AUTOSAR XML (schema 4-2-1)
standard types defined: float32, float64, sint8, sint16, sint32, uint8, uint16, uint32, boolean, dtRef_VOID, Float32, Boolean, UInt32
package /FoundationPkg/FoundationArchitecturePkg
  constant specification iAssistTorque_AssistanceTorque_Init: value-spec={short-label=iAssistTorque_AssistanceTorque_Init, fields=[0 Nm, 0]}
  sender receiver interface iAssistTorque
    data AssistanceTorque: sw-calibration-access=READ-ONLY, type=tAssistTorque, init-value=constant-reference=iAssistTorque_AssistanceTorque_Init
  constant specification iAssistCapability_Capability_Init: value-spec={short-label=iAssistCapability_Capability_Init, fields=[0 %, 0 %]}
  sender receiver interface iAssistCapability
    data Capability: sw-calibration-access=READ-ONLY, type=tAssistCapability, init-value=constant-reference=iAssistCapability_Capability_Init
  constant specification iAssistCapabilityLimit_CapabilityLimit_Init: value-spec=0 %
  sender receiver interface iAssistCapabilityLimit
    data CapabilityLimit: sw-calibration-access=READ-ONLY, type=Percent, init-value=constant-reference=iAssistCapabilityLimit_CapabilityLimit_Init
  constant specification iVehicleData_VehicleSpeed_Init: value-spec={short-label=iVehicleData_VehicleSpeed_Init, fields=[0 Kph, 0, 0]}
  constant specification iVehicleData_EstimatedSteeringPosition_Init: value-spec={short-label=iVehicleData_EstimatedSteeringPosition_Init, fields=[0 deg, 0, 0 %]}
  constant specification iVehicleData_YawRate_Init: value-spec={short-label=iVehicleData_YawRate_Init, fields=[0 deg/S, 0]}
  sender receiver interface iVehicleData
    data VehicleSpeed: sw-calibration-access=READ-ONLY, type=tVehicleSpd, init-value=constant-reference=iVehicleData_VehicleSpeed_Init
    data EstimatedSteeringPosition: sw-calibration-access=READ-ONLY, type=tEstimatedSteeringPosition, init-value=constant-reference=iVehicleData_EstimatedSteeringPosition_Init
    data YawRate: sw-calibration-access=READ-ONLY, type=tYawRateData, init-value=constant-reference=iVehicleData_YawRate_Init
  5 x constant specification:
    iColumnData_ColumnTorque_Init: value-spec={short-label=iColumnData_ColumnTorque_Init, fields=[0 Nm, 0 Nm/s, 0]}
    iColumnData_SteeringPositionLower_Init: value-spec={short-label=iColumnData_SteeringPositionLower_Init, fields=[0 deg, 0, {short-label=tColumnPosition_EQf_Init, fields=[1, 1, 1, 1]}]}
    iColumnData_ColumnVelocity_Init: value-spec={short-label=iColumnData_ColumnVelocity_Init, fields=[0 revs/S, 0 revs/S, 0]}
    iColumnData_SteeringPositionUpper_Init: value-spec={short-label=iColumnData_SteeringPositionUpper_Init, fields=[0 deg, 0, {short-label=tColumnPosition_EQf_Init, fields=[1, 1, 1, 1]}]}
    iColumnData_ColumnPositionLower_Init: value-spec={short-label=iColumnData_ColumnPositionLower_Init, fields=[0 deg, 0, {short-label=tColumnPosition_EQf_Init, fields=[1, 1, 1, 1]}]}
  sender receiver interface iColumnData
    5 x data, all with sw-calibration-access=READ-ONLY:
      ColumnTorque: type=tInputTorque, init-value=constant-reference=iColumnData_ColumnTorque_Init
      SteeringPositionLower: type=tColumnPosition, init-value=constant-reference=iColumnData_SteeringPositionLower_Init
      ColumnVelocity: type=tColumnVelocity, init-value=constant-reference=iColumnData_ColumnVelocity_Init
      SteeringPositionUpper: type=tColumnPosition, init-value=constant-reference=iColumnData_SteeringPositionUpper_Init
      ColumnPositionLower: type=tColumnPosition, init-value=constant-reference=iColumnData_ColumnPositionLower_Init
  client server interface iRack
    8 x operation:
      getMaxPhysicalAssist
        arg maxPhysicalAssist: type=Nm, direction=OUT
      initialisationColumnAngle
        arg pinionAngle: type=Degrees, direction=IN
      translateColumnAngleToRackPosition
        arg pinionAngle: type=Degrees, direction=IN
        arg rackPosition: type=mm, direction=OUT
      translateColumnTorqueToRackForce
        arg columnTorque: type=Nm, direction=IN
        arg rackForce: type=kN, direction=OUT
      translateRackPositionToColumnAngle
        arg rackPosition: type=mm, direction=IN
        arg columnAngle: type=Degrees, direction=OUT
      translateRackForceToColumnTorque
        arg rackForce: type=kN, direction=IN
        arg columnTorque: type=Nm, direction=OUT
      translateColumnVelocityToRackVelocity
        arg columnVelocity: type=DegreesPerSec, direction=IN
        arg rackVelocity: type=mmPerSec, direction=OUT
      translateRackVelocityToColumnVelocity
        arg rackVelocity: type=mmPerSec, direction=IN
        arg columnVelocity: type=DegreesPerSec, direction=OUT
  constant specification iFitness_ControllerFitness_Init: value-spec=3
  sender receiver interface iFitness
    data ControllerFitness: sw-calibration-access=READ-ONLY, type=tQualityFactor, init-value=constant-reference=iFitness_ControllerFitness_Init
  client server interface iElectricDriveControl
    operation enable
    operation getEnableState
      4 x arg, all with direction=OUT:
        state: type=tEnableState
        bridge1Health: type=tHealthStatus
        bridge2Health: type=tHealthStatus
        maxTimeCapability: type=tMaxTimeCapability
    operation disable
  constant specification iAssistStates_AssistState_Init: value-spec={short-label=iAssistStates_AssistState_Init, fields=[0, 1]}
  sender receiver interface iAssistStates
    data AssistState: sw-calibration-access=READ-ONLY, type=tAssistStates, init-value=constant-reference=iAssistStates_AssistState_Init
  constant specification iSegControl_SegEnStatus_Init: value-spec=0
  constant specification iSegControl_SegMode_Init: value-spec=0
  constant specification iSegControl_SegElecDrvDisableReq_Init: value-spec=0
  sender receiver interface iSegControl
    data SegEnStatus: sw-calibration-access=READ-ONLY, type=Boolean, init-value=constant-reference=iSegControl_SegEnStatus_Init
    data SegMode: sw-calibration-access=READ-ONLY, type=tSegMode, init-value=constant-reference=iSegControl_SegMode_Init
    data SegElecDrvDisableReq: sw-calibration-access=READ-ONLY, type=Boolean, init-value=constant-reference=iSegControl_SegElecDrvDisableReq_Init
  client server interface iOveruseControl
    operation setOveruseInhibition
      arg RequestInhibition: type=Boolean, direction=IN
package /FoundationPkg/FoundationArchitecturePkg/FoundationControllerPkg
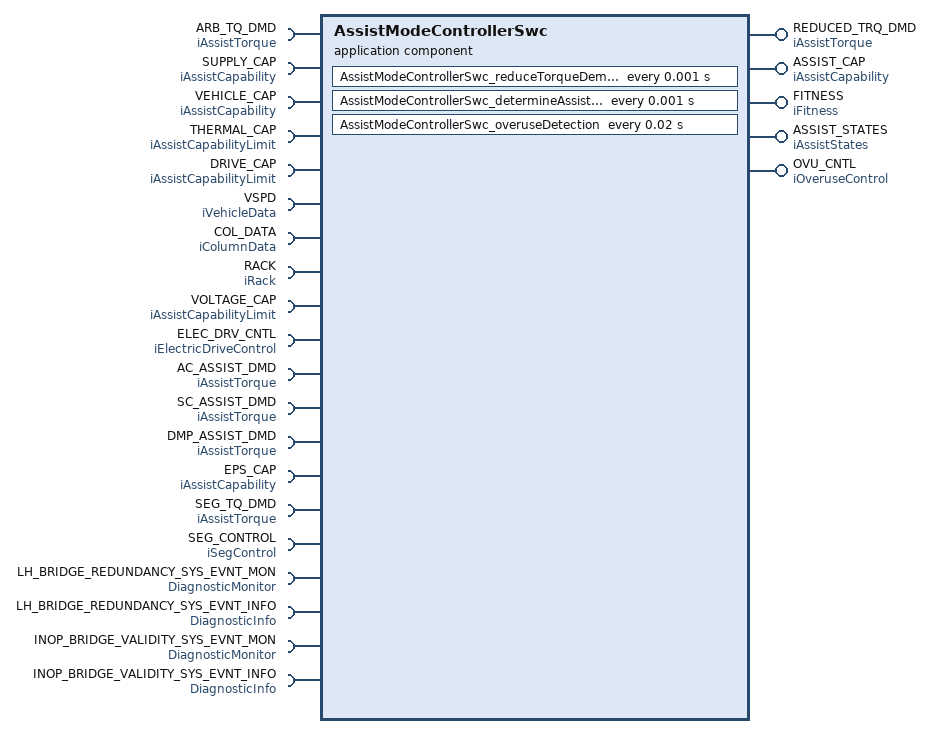
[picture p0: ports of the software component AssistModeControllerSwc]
  application sw component type AssistModeControllerSwc  # Based on the input states representing the capability of either the vehicle or the components of the EPS System reduce the assistance torque demand to prevent that demand exceeding the current capability of the input with the lowest capability. The function must also take account of any reinstatement of system capability from exceeding the maximum rate of torque reinstatement.
    require port ARB_TQ_DMD: nonqueued-receiver-com-spec{data-element=AssistanceTorque, init-value=constant-reference=iAssistTorque_AssistanceTorque_Init}, required-interface=iAssistTorque
    provide port REDUCED_TRQ_DMD: nonqueued-sender-com-spec{data-element=AssistanceTorque, init-value=constant-reference=iAssistTorque_AssistanceTorque_Init}, provided-interface=iAssistTorque
    6 x require port:
      SUPPLY_CAP: nonqueued-receiver-com-spec{data-element=Capability, init-value=constant-reference=iAssistCapability_Capability_Init}, required-interface=iAssistCapability
      VEHICLE_CAP: nonqueued-receiver-com-spec{data-element=Capability, init-value=constant-reference=iAssistCapability_Capability_Init}, required-interface=iAssistCapability
      THERMAL_CAP: nonqueued-receiver-com-spec{data-element=CapabilityLimit, init-value=constant-reference=iAssistCapabilityLimit_CapabilityLimit_Init}, required-interface=iAssistCapabilityLimit
      DRIVE_CAP: nonqueued-receiver-com-spec{data-element=CapabilityLimit, init-value=constant-reference=iAssistCapabilityLimit_CapabilityLimit_Init}, required-interface=iAssistCapabilityLimit
      VSPD: required-interface=iVehicleData
        required-com-specs:
          data-element=VehicleSpeed, init-value=constant-reference=iVehicleData_VehicleSpeed_Init
          data-element=EstimatedSteeringPosition, init-value=constant-reference=iVehicleData_EstimatedSteeringPosition_Init
          data-element=YawRate, init-value=constant-reference=iVehicleData_YawRate_Init
      COL_DATA: required-interface=iColumnData
        required-com-specs:
          data-element=ColumnTorque, init-value=constant-reference=iColumnData_ColumnTorque_Init
          data-element=SteeringPositionLower, init-value=constant-reference=iColumnData_SteeringPositionLower_Init
          data-element=ColumnVelocity, init-value=constant-reference=iColumnData_ColumnVelocity_Init
          data-element=SteeringPositionUpper, init-value=constant-reference=iColumnData_SteeringPositionUpper_Init
          data-element=ColumnPositionLower, init-value=constant-reference=iColumnData_ColumnPositionLower_Init
    provide port ASSIST_CAP: nonqueued-sender-com-spec{data-element=Capability, init-value=constant-reference=iAssistCapability_Capability_Init}, provided-interface=iAssistCapability
    require port RACK: required-interface=iRack
    provide port FITNESS: nonqueued-sender-com-spec{data-element=ControllerFitness, init-value=constant-reference=iFitness_ControllerFitness_Init}, provided-interface=iFitness
    require port VOLTAGE_CAP: nonqueued-receiver-com-spec{data-element=CapabilityLimit, init-value=constant-reference=iAssistCapabilityLimit_CapabilityLimit_Init}, required-interface=iAssistCapabilityLimit
    require port ELEC_DRV_CNTL: required-interface=iElectricDriveControl
    provide port ASSIST_STATES: nonqueued-sender-com-spec{data-element=AssistState, init-value=constant-reference=iAssistStates_AssistState_Init}, provided-interface=iAssistStates
    6 x require port:
      AC_ASSIST_DMD: nonqueued-receiver-com-spec{data-element=AssistanceTorque, init-value=constant-reference=iAssistTorque_AssistanceTorque_Init}, required-interface=iAssistTorque
      SC_ASSIST_DMD: nonqueued-receiver-com-spec{data-element=AssistanceTorque, init-value=constant-reference=iAssistTorque_AssistanceTorque_Init}, required-interface=iAssistTorque
      DMP_ASSIST_DMD: nonqueued-receiver-com-spec{data-element=AssistanceTorque, init-value=constant-reference=iAssistTorque_AssistanceTorque_Init}, required-interface=iAssistTorque
      EPS_CAP: nonqueued-receiver-com-spec{data-element=Capability, init-value=constant-reference=iAssistCapability_Capability_Init}, required-interface=iAssistCapability  # The EPS assist capability, as a result of EPS diagnostic monitoring
      SEG_TQ_DMD: nonqueued-receiver-com-spec{data-element=AssistanceTorque, init-value=constant-reference=iAssistTorque_AssistanceTorque_Init}, required-interface=iAssistTorque
      SEG_CONTROL: required-interface=iSegControl
        required-com-specs:
          data-element=SegEnStatus, init-value=constant-reference=iSegControl_SegEnStatus_Init
          data-element=SegMode, init-value=constant-reference=iSegControl_SegMode_Init
          data-element=SegElecDrvDisableReq, init-value=constant-reference=iSegControl_SegElecDrvDisableReq_Init
    provide port OVU_CNTL: server-com-spec{operation=setOveruseInhibition, queue-length=1}, provided-interface=iOveruseControl
    4 x require port:
      LH_BRIDGE_REDUNDANCY_SYS_EVNT_MON: required-interface=DiagnosticMonitor
      LH_BRIDGE_REDUNDANCY_SYS_EVNT_INFO: required-interface=DiagnosticInfo
      INOP_BRIDGE_VALIDITY_SYS_EVNT_MON: required-interface=DiagnosticMonitor
      INOP_BRIDGE_VALIDITY_SYS_EVNT_INFO: required-interface=DiagnosticInfo
    behavior AssistModeControllerSwc_IB: data-type-mapping=MappingSet, handle-termination-and-restart=NO-SUPPORT
      timing event Event_reduceTorqueDemand: start-on-event=AssistModeControllerSwc_reduceTorqueDemand, period=0.001
      timing event Event_determineAssistState: start-on-event=AssistModeControllerSwc_determineAssistState, period=0.001
      timing event Event_overuseDetection: start-on-event=AssistModeControllerSwc_overuseDetection, period=0.02
      init event Event_initialiser_Init: start-on-event=AssistModeControllerSwc_initialiser
      operation invoked event Event_setOveruseInhibition: start-on-event=AssistModeControllerSwc_setOveruseInhibition, operation=OVU_CNTL.setOveruseInhibition
      explicit-inter-runnable-variables:
        data OveruseInhibited: sw-calibration-access=READ-ONLY, type=Boolean, init-value=constant-reference=AssistModeControllerSwc_OveruseInhibited_Init  # The IRV indicates if there is one source requesting overuse suppressing.
      implicit-inter-runnable-variables:
        6 x data, all with sw-calibration-access=READ-ONLY:
          OveruseCapability_Limit: type=Percent, init-value=constant-reference=OveruseCapability_Limit_Init  # Limit as a percentage of the total system assist capability.
          OveruseCapability_Scale: type=Percent, init-value=constant-reference=OveruseCapability_Scale_Init  # Limit as a percentage of the assistance demand i.e. reducing the demand by a percentage.
          AssistStateCapability_Limit: type=Percent, init-value=constant-reference=AssistStateCapability_Limit_Init  # Limit as a percentage of the total system assist capability.
          AssistStateCapability_Scale: type=Percent, init-value=constant-reference=AssistStateCapability_Scale_Init  # Limit as a percentage of the assistance demand i.e. reducing the demand by a percentage.
          RedAssistanceTorque_Value: type=Nm, init-value=constant-reference=RedAssistanceTorque_Value_Init
          RedAssistanceTorque_Qf: type=tQualityFactor, init-value=constant-reference=RedAssistanceTorque_Qf_Init
      per-instance-parameters:
        13 x parameter data prototype, all with category=VALUE, sw-addr-method=PlatformTune, sw-calibration-access=READ-WRITE:
          OVERUSE_LIMIT_VSPD_THRESHOLD: type=Kph_0_0_to_400_0, init-value=constant-reference=PlatformTune_OVERUSE_LIMIT_VSPD_THRESHOLD_Init  # Vehicle speed above which overuse will not reduce assist.
          OVERUSE_COLUMN_VELOCITY_THRESHOLD: type=RevsPerSec_0_0_to_0_5, init-value=constant-reference=PlatformTune_OVERUSE_COLUMN_VELOCITY_THRESHOLD_Init  # Column Velocity threshold above which Overuse will not reduce assist.
          OVERUSE_INITIATION_TIME: type=ms_0_to_2500, init-value=constant-reference=PlatformTune_OVERUSE_INITIATION_TIME_Init  # Time overuse conditions must be present before overuse starts to reduce assist.
          OVERUSE_TORQUE_LIMIT_VALUE: type=Percent_0_0_to_1_0, init-value=constant-reference=PlatformTune_OVERUSE_TORQUE_LIMIT_VALUE_Init  # Column torque value below which overuse will not reduce assist.
          OVERUSE_TORQUE_LIMIT_DOWN_SLEW_RATE: type=PercentPerSec_0_1_to_50_0, init-value=constant-reference=PlatformTune_OVERUSE_TORQUE_LIMIT_DOWN_SLEW_RATE_Init  # Slew rate for overuse to ramp assist down.
          OVERUSE_TORQUE_LIMIT_UP_SLEW_RATE: type=PercentPerSec_0_1_to_50_0, init-value=constant-reference=PlatformTune_OVERUSE_TORQUE_LIMIT_UP_SLEW_RATE_Init  # Slew rate for overuse to ramp assist back in.
          OVERUSE_UPPER_ASSIST_TORQUE_PERCENT_THRESHOLD: type=Percent_0_to_1, init-value=constant-reference=PlatformTune_OVERUSE_UPPER_ASSIST_TORQUE_PERCENT_THRESHOLD_Init  # Target assist level for overuse to reduce torque to.
          OVERUSE_LOWER_ASSIST_TORQUE_PERCENT_THRESHOLD: type=Percent_0_to_1, init-value=constant-reference=PlatformTune_OVERUSE_LOWER_ASSIST_TORQUE_PERCENT_THRESHOLD_Init  # Target assist level for overuse to reduce torque to.
          SUDDEN_CHANGE_INC_TRQ_SFB: type=PercentPerSec_1_to_100, init-value=constant-reference=PlatformTune_SUDDEN_CHANGE_INC_TRQ_SFB_Init  # This parameter represents the maximum rate at which assist can be ramped up. It is used to rampup the voltage, thermal and drive capabilities from the EPP.
          LIMP_HOME_EPP_CAPABILITY_TRANSITION_TIME: type=ms_500_to_5000, init-value=constant-reference=PlatformTune_LIMP_HOME_EPP_CAPABILITY_TRANSITION_TIME_Init  # Time to transition to the reduced (scale) assist after an EPP failure resulting in reduced EPP capability. A smooth transition ramp will be used from the current assist capability to the reduce capability.
          LIMP_HOME_TARGET_CAP_LIMIT: type=Percent_0_to_1, init-value=constant-reference=PlatformTune_LIMP_HOME_TARGET_CAP_LIMIT_Init  # Maximal provided assist in percentage (calculated based on max physical assist) whilst limp home mode.
          LIMP_HOME_TARGET_CAP_SCALE: type=Percent_0_to_1, init-value=constant-reference=PlatformTune_LIMP_HOME_TARGET_CAP_SCALE_Init  # Boost curve scale factor in percentage whilst limp home mode.
          LIMITED_ASSIST_WITH_OVERUSE: type=Boolean, init-value=constant-reference=PlatformTune_LIMITED_ASSIST_WITH_OVERUSE_Init  # Tune controls if the an overuse case shall cause a limited assit. The torque reduction due to overuse will always happen independently from this tune. True: an overuse case will cause a limited asssit False: an overuse case will not cause a limited assist
      5 x runnable:
        AssistModeControllerSwc_reduceTorqueDemand: symbol=AssistModeController_reduceTorqueDemand  # Reduce the torque demand by applying the lowest of the input torque demands. Two types of limiting are supported: SCALE - reduce the torque by a percentage of the assistance torque demand. LIMIT - limit the torque by a percentage of the maximum assist capability of the EPS system. This function shall also guard against large step changes in torque reinstatement by enforcing a maximum reinstatement torque limit (SUDDEN_CHANGE_INC_TRQ_SFB).
          data-read-access:
            access R_ARB_TQ_DMD_AssistanceTorque: accessed-variable=ARB_TQ_DMD.AssistanceTorque
            access R_VSPD_VehicleSpeed: accessed-variable=VSPD.VehicleSpeed
            access R_SEG_TQ_DMD_AssistanceTorque: accessed-variable=SEG_TQ_DMD.AssistanceTorque
          data-write-access:
            access W_REDUCED_TRQ_DMD_AssistanceTorque: accessed-variable=REDUCED_TRQ_DMD.AssistanceTorque
          parameter access SUDDEN_CHANGE_INC_TRQ_SFB: accessed-parameter=SUDDEN_CHANGE_INC_TRQ_SFB
          read-local-variables:
            access RV_AssistStateCapability_Limit: accessed-variable=AssistStateCapability_Limit
            access RV_AssistStateCapability_Scale: accessed-variable=AssistStateCapability_Scale
          sync call Call_RACK_getMaxPhysicalAssist: operation=RACK.getMaxPhysicalAssist
          written-local-variables:
            access WV_RedAssistanceTorque_Value: accessed-variable=RedAssistanceTorque_Value
            access WV_RedAssistanceTorque_Qf: accessed-variable=RedAssistanceTorque_Qf
        AssistModeControllerSwc_determineAssistState: symbol=AssistModeController_determineAssistState  # This runnable determines the assist states based on the assist capability and environment condition of the system. Assist states are used to determine the system states (Fully assisted, Limited assisted or failure conditions). Assist states directly controls the assist level or the system and this is one of the important feature which decides the reduction in the torque demand to motor. Assist states are also necessary to the fault tolerance of the system and take preventive measures.
          data-read-access:
            14 x access:
              R_COL_DATA_ColumnTorque: accessed-variable=COL_DATA.ColumnTorque
              R_COL_DATA_ColumnVelocity: accessed-variable=COL_DATA.ColumnVelocity
              R_SUPPLY_CAP_Capability: accessed-variable=SUPPLY_CAP.Capability
              R_VEHICLE_CAP_Capability: accessed-variable=VEHICLE_CAP.Capability
              R_THERMAL_CAP_CapabilityLimit: accessed-variable=THERMAL_CAP.CapabilityLimit
              R_DRIVE_CAP_CapabilityLimit: accessed-variable=DRIVE_CAP.CapabilityLimit
              R_VOLTAGE_CAP_CapabilityLimit: accessed-variable=VOLTAGE_CAP.CapabilityLimit
              R_AC_ASSIST_DMD_AssistanceTorque: accessed-variable=AC_ASSIST_DMD.AssistanceTorque
              R_SC_ASSIST_DMD_AssistanceTorque: accessed-variable=SC_ASSIST_DMD.AssistanceTorque
              R_DMP_ASSIST_DMD_AssistanceTorque: accessed-variable=DMP_ASSIST_DMD.AssistanceTorque
              R_EPS_CAP_Capability: accessed-variable=EPS_CAP.Capability
              R_SEG_CONTROL_SegEnStatus: accessed-variable=SEG_CONTROL.SegEnStatus
              R_SEG_CONTROL_SegMode: accessed-variable=SEG_CONTROL.SegMode
              R_SEG_CONTROL_SegElecDrvDisableReq: accessed-variable=SEG_CONTROL.SegElecDrvDisableReq
          data-write-access:
            access W_FITNESS_ControllerFitness: accessed-variable=FITNESS.ControllerFitness
            access W_ASSIST_CAP_Capability: accessed-variable=ASSIST_CAP.Capability
            access W_ASSIST_STATES_AssistState: accessed-variable=ASSIST_STATES.AssistState
          4 x parameter access:
            LIMP_HOME_EPP_CAPABILITY_TRANSITION_TIME: accessed-parameter=LIMP_HOME_EPP_CAPABILITY_TRANSITION_TIME
            LIMP_HOME_TARGET_CAP_LIMIT: accessed-parameter=LIMP_HOME_TARGET_CAP_LIMIT
            LIMP_HOME_TARGET_CAP_SCALE: accessed-parameter=LIMP_HOME_TARGET_CAP_SCALE
            LIMITED_ASSIST_WITH_OVERUSE: accessed-parameter=LIMITED_ASSIST_WITH_OVERUSE
          read-local-variables:
            access RV_OveruseCapability_Limit: accessed-variable=OveruseCapability_Limit
            access RV_OveruseCapability_Scale: accessed-variable=OveruseCapability_Scale
          10 x sync call:
            Call_ELEC_DRV_CNTL_getEnableState: operation=ELEC_DRV_CNTL.getEnableState
            Call_ELEC_DRV_CNTL_disable: operation=ELEC_DRV_CNTL.disable
            Call_INOP_BRIDGE_VALIDITY_SYS_EVNT_SetEventStatus: operation=INOP_BRIDGE_VALIDITY_SYS_EVNT_MON.SetEventStatus
            Call_INOP_BRIDGE_VALIDITY_SYS_EVNT_ResetEventStatus: operation=INOP_BRIDGE_VALIDITY_SYS_EVNT_MON.ResetEventDebounceStatus
            Call_INOP_BRIDGE_VALIDITY_SYS_EVNT_GetEventStatus: operation=INOP_BRIDGE_VALIDITY_SYS_EVNT_INFO.GetEventStatus
            Call_INOP_BRIDGE_VALIDITY_SYS_EVNT_GetEventFailed: operation=INOP_BRIDGE_VALIDITY_SYS_EVNT_INFO.GetEventFailed
            Call_LH_BRIDGE_REDUNDANCY_SYS_EVNT_SetEventStatus: operation=LH_BRIDGE_REDUNDANCY_SYS_EVNT_MON.SetEventStatus
            Call_LH_BRIDGE_REDUNDANCY_SYS_EVNT_ResetEventStatus: operation=LH_BRIDGE_REDUNDANCY_SYS_EVNT_MON.ResetEventDebounceStatus
            Call_LH_BRIDGE_REDUNDANCY_SYS_EVNT_GetEventStatus: operation=LH_BRIDGE_REDUNDANCY_SYS_EVNT_INFO.GetEventStatus
            Call_LH_BRIDGE_REDUNDANCY_SYS_EVNT_GetEventFailed: operation=LH_BRIDGE_REDUNDANCY_SYS_EVNT_INFO.GetEventFailed
          written-local-variables:
            access WV_AssistStateCapability_Limit: accessed-variable=AssistStateCapability_Limit
            access WV_AssistStateCapability_Scale: accessed-variable=AssistStateCapability_Scale
        AssistModeControllerSwc_overuseDetection: symbol=AssistModeController_overuseDetection  # The purpose of the overuse function is to take early intervention to reduce the torque demand in conditions when the EPP may start to get hot (high torque demand, low column velocities). Overuse takes action to reduce the torque demand thereby preventing the system going into thermal derating. By taking preventative action the system will not have got warm and derated when the steering is required again. Detect the conditions for system overuse and when present request a reduction in the torque demand.
          data-read-access:
            4 x access:
              R_VSPD_VehicleSpeed: accessed-variable=VSPD.VehicleSpeed
              R_COL_DATA_ColumnVelocity: accessed-variable=COL_DATA.ColumnVelocity
              R_ARB_TQ_DMD_AssistanceTorque: accessed-variable=ARB_TQ_DMD.AssistanceTorque
              R_SEG_TQ_DMD_AssistanceTorque: accessed-variable=SEG_TQ_DMD.AssistanceTorque
          8 x parameter access:
            OVERUSE_COLUMN_VELOCITY_THRESHOLD: accessed-parameter=OVERUSE_COLUMN_VELOCITY_THRESHOLD
            OVERUSE_INITIATION_TIME: accessed-parameter=OVERUSE_INITIATION_TIME
            OVERUSE_LIMIT_VSPD_THRESHOLD: accessed-parameter=OVERUSE_LIMIT_VSPD_THRESHOLD
            OVERUSE_TORQUE_LIMIT_DOWN_SLEW_RATE: accessed-parameter=OVERUSE_TORQUE_LIMIT_DOWN_SLEW_RATE
            OVERUSE_TORQUE_LIMIT_UP_SLEW_RATE: accessed-parameter=OVERUSE_TORQUE_LIMIT_UP_SLEW_RATE
            OVERUSE_TORQUE_LIMIT_VALUE: accessed-parameter=OVERUSE_TORQUE_LIMIT_VALUE
            OVERUSE_LOWER_ASSIST_TORQUE_PERCENT_THRESHOLD: accessed-parameter=OVERUSE_LOWER_ASSIST_TORQUE_PERCENT_THRESHOLD
            OVERUSE_UPPER_ASSIST_TORQUE_PERCENT_THRESHOLD: accessed-parameter=OVERUSE_UPPER_ASSIST_TORQUE_PERCENT_THRESHOLD
          read-local-variables:
            access RV_RedAssistanceTorque_Value: accessed-variable=RedAssistanceTorque_Value
            access RV_RedAssistanceTorque_Qf: accessed-variable=RedAssistanceTorque_Qf
            access RV_OveruseInhibited: accessed-variable=OveruseInhibited
          sync call Call_RACK_getMaxPhysicalAssist: operation=RACK.getMaxPhysicalAssist
          written-local-variables:
            access WV_OveruseCapability_Limit: accessed-variable=OveruseCapability_Limit
            access WV_OveruseCapability_Scale: accessed-variable=OveruseCapability_Scale
        AssistModeControllerSwc_initialiser: symbol=AssistModeController_initialiser
        AssistModeControllerSwc_setOveruseInhibition: symbol=AssistModeController_setOveruseInhibition  # Interface requests the inhibition of an possible overuse torque reduction. 1. RequestInhibition set to true: torque shall not be reduced due to overuse. 2. RequestInhibition set to false: torque shall be reduced due to overuse. The interface is reenterable. Each client is required to clear the inhibition by setting RequestInhibition to false once the inhibition is no longer needed. Otherwise the overuse will stay inhibited till end of the current ignition.
          written-local-variables:
            access WV_OveruseInhibited: accessed-variable=OveruseInhibited
      4 x swc service dependency:
        Monitor_LH_BRIDGE_REDUNDANCY_SYS_EVNT: assigned-ports=role-based-port-assignment={port-prototype=LH_BRIDGE_REDUNDANCY_SYS_EVNT_MON, role=DiagnosticMonitor}
          service-needs:
            diagnostic event needs EventNeed_LH_BRIDGE_REDUNDANCY_SYS_EVNT
        Info_LH_BRIDGE_REDUNDANCY_SYS_EVNT: assigned-ports=role-based-port-assignment={port-prototype=LH_BRIDGE_REDUNDANCY_SYS_EVNT_INFO, role=DiagnosticInfo}
          service-needs:
            diagnostic event info needs InfoNeed_LH_BRIDGE_REDUNDANCY_SYS_EVNT
        Monitor_INOP_BRIDGE_VALIDITY_SYS_EVNT: assigned-ports=role-based-port-assignment={port-prototype=INOP_BRIDGE_VALIDITY_SYS_EVNT_MON, role=DiagnosticMonitor}
          service-needs:
            diagnostic event needs EventNeed_INOP_BRIDGE_VALIDITY_SYS_EVNT
        Info_INOP_BRIDGE_VALIDITY_SYS_EVNT: assigned-ports=role-based-port-assignment={port-prototype=INOP_BRIDGE_VALIDITY_SYS_EVNT_INFO, role=DiagnosticInfo}
          service-needs:
            diagnostic event info needs InfoNeed_INOP_BRIDGE_VALIDITY_SYS_EVNT
  14 x constant specification:
    AssistModeControllerSwc_OveruseInhibited_Init: value-spec=0
    PlatformTune_OVERUSE_LIMIT_VSPD_THRESHOLD_Init: value-spec=2.0
    PlatformTune_OVERUSE_COLUMN_VELOCITY_THRESHOLD_Init: value-spec=0.1
    PlatformTune_OVERUSE_INITIATION_TIME_Init: value-spec=500
    PlatformTune_OVERUSE_TORQUE_LIMIT_VALUE_Init: value-spec=0.6
    PlatformTune_OVERUSE_TORQUE_LIMIT_DOWN_SLEW_RATE_Init: value-spec=0.63
    PlatformTune_OVERUSE_TORQUE_LIMIT_UP_SLEW_RATE_Init: value-spec=1.0
    PlatformTune_OVERUSE_UPPER_ASSIST_TORQUE_PERCENT_THRESHOLD_Init: value-spec=0.95
    PlatformTune_OVERUSE_LOWER_ASSIST_TORQUE_PERCENT_THRESHOLD_Init: value-spec=0.6
    PlatformTune_SUDDEN_CHANGE_INC_TRQ_SFB_Init: value-spec=1.0
    PlatformTune_LIMP_HOME_EPP_CAPABILITY_TRANSITION_TIME_Init: value-spec=1000
    PlatformTune_LIMP_HOME_TARGET_CAP_LIMIT_Init: value-spec=0.5
    PlatformTune_LIMP_HOME_TARGET_CAP_SCALE_Init: value-spec=0.5
    PlatformTune_LIMITED_ASSIST_WITH_OVERUSE_Init: value-spec=1
package /FoundationPkg/FoundationArchitecturePkg/FoundationTypes
  unit Nm_Unit: display-name=Nm
  impl type Nm: implementation-data-type=Float32
  compu method tQualityFactor_Compu: 0=QF_UNINITIALIZED, 0=QF_UNINITIALISED, 1=QF_UNAVAILABLE, 2=QF_DEGRADED, 3=QF_FULL
  impl type tQualityFactor: category=VALUE, base-type=sint32, compu-method=tQualityFactor_Compu
  impl type tAssistTorque: category=STRUCTURE
    element Value: implementation-data-type=Nm
    element Qf: implementation-data-type=tQualityFactor
  unit Percent_Unit: display-name=%
  impl type Percent: implementation-data-type=Float32
  impl type tAssistCapability: category=STRUCTURE
    element Limit: implementation-data-type=Percent
    element Scale: implementation-data-type=Percent
  unit Kph_Unit: display-name=Kph
  impl type Kph: implementation-data-type=Float32
  impl type tVehicleSpd: category=STRUCTURE
    element Filtered: implementation-data-type=Kph
    element Moving: implementation-data-type=Boolean
    element Qf: implementation-data-type=tQualityFactor
  unit Degrees_Unit: display-name=deg
  impl type Degrees: implementation-data-type=Float32
  impl type tEstimatedSteeringPosition: category=STRUCTURE
    element Value: implementation-data-type=Degrees
    element Qf: implementation-data-type=tQualityFactor
    element Confidence: implementation-data-type=Percent
  unit DegreesPerSec_Unit: display-name=deg/S
  impl type DegreesPerSec: implementation-data-type=Float32
  impl type tYawRateData: category=STRUCTURE
    element Value: implementation-data-type=DegreesPerSec
    element Qf: implementation-data-type=tQualityFactor
  unit NmPerSec_Unit: display-name=Nm/s
  4 x impl type:
    NmPerSec: implementation-data-type=Float32
    tInputTorque: category=STRUCTURE
      element Value: implementation-data-type=Nm
      element Derivative: implementation-data-type=NmPerSec
      element Qf: implementation-data-type=tQualityFactor
    tExtendedQf: category=STRUCTURE
      4 x element, all with category=TYPE_REFERENCE, implementation-data-type=Boolean:
        IntegrityDegraded
        ResolutionDegraded
        LossOfRedundancy
        Defaulted
    tColumnPosition: category=STRUCTURE
      element Value: implementation-data-type=Degrees
      element Qf: implementation-data-type=tQualityFactor
      element EQf: implementation-data-type=tExtendedQf
  unit RevsPerSec_Unit: display-name=revs/S
  impl type RevsPerSec: implementation-data-type=Float32
  impl type tColumnVelocity: category=STRUCTURE
    element Filtered: implementation-data-type=RevsPerSec
    element Unfiltered: implementation-data-type=RevsPerSec
    element Qf: implementation-data-type=tQualityFactor
  unit mm_Unit: display-name=mm
  impl type mm: implementation-data-type=Float32
  unit kN_Unit: display-name=kN
  impl type kN: implementation-data-type=Float32
  unit mmPerSec_Unit: display-name=mm/s
  impl type mmPerSec: implementation-data-type=Float32
  impl type tEnableState: category=VALUE, base-type=sint32, compu {0=ES_DISABLE, 1=ES_NOT_READY, 2=ES_ENABLE, 3=ES_SHUTTING_DOWN}
  impl type tHealthStatus: category=VALUE, base-type=sint32, compu {0=HEALTH_NOT_CONFIGURED, 1=HEALTHY, 2=HEALTH_FAILED}
  impl type tMaxTimeCapability: category=VALUE, base-type=sint32, compu {0=TIME_30HRS, 1=TIME_11MIN, 2=TIME_10SEC, 3=TIME_UNLIMITED}
  compu method tAssistMode_Compu: 0=ASSIST_INIT, 1=ASSIST_NORMAL_OPERATION, 2=ASSIST_FAIL_OPERATIONAL, 3=ASSIST_LIMP_HOME, 4=ASSIST_LIMP_ASIDE, 5=ASSIST_INOPERATIVE
  impl type tAssistMode: category=VALUE, base-type=sint32, compu-method=tAssistMode_Compu
  impl type tLimitedAssistMode: category=VALUE, base-type=sint32, compu {0=ASSIST_NOT_LIMITED, 1=ASSIST_LIMITED}
  impl type tAssistStates: category=STRUCTURE
    element AssistMode: implementation-data-type=tAssistMode
    element LimitedAssistMode: implementation-data-type=tLimitedAssistMode
  compu method tSegMode_Compu: 0=OLSYS_CHAR, 1=CLSYS_CNTR_CHAR, 2=OLSYS_CNTR_CHAR, 3=OLCNTR_CHAR, 4=OLSYS_HAZ_CHAR, 5=CLSYS_HAZ_CNTR_CHAR
  impl type tSegMode: category=VALUE, base-type=sint32, compu-method=tSegMode_Compu
  6 x constant specification:
    OveruseCapability_Limit_Init: value-spec=0.0
    OveruseCapability_Scale_Init: value-spec=0
    AssistStateCapability_Limit_Init: value-spec=0.0
    AssistStateCapability_Scale_Init: value-spec=0.0
    RedAssistanceTorque_Value_Init: value-spec=0.0
    RedAssistanceTorque_Qf_Init: value-spec=0
  unit ms_Unit: display-name=mS
  impl type ms: implementation-data-type=UInt32
  unit PercentPerSec_Unit: display-name=%/s
  impl type PercentPerSec: implementation-data-type=Float32
package /FoundationPkg/FoundationArchitecturePkg/FoundationTypes/ApplicationTypesPkg
  app type Nm_n255_0_to_255_0: category=VALUE, compu {identical; unit Nm}, range phys -255..255, unit=Nm
  app type Float32: category=VALUE, compu {identical}
  app type tQualityFactor: category=VALUE, base-type=sint32, compu-method=tQualityFactor_Compu  # Describes the quality of an input signal.
  application record data type tAssistTorque: category=STRUCTURE
    application record element Value: category=VALUE, type=Nm_n255_0_to_255_0
    application record element Qf: category=VALUE, type=tQualityFactor
  app type Nm: category=VALUE, compu {identical; unit Nm}, range phys -10..10, unit=Nm
  app type Percent: category=VALUE, compu {identical; unit %}, range phys 0..100, unit=%
  application record data type tAssistCapability: category=STRUCTURE
    application record element Limit: category=VALUE, type=Percent
    application record element Scale: category=VALUE, type=Percent
  app type Kph_0_to_400: category=VALUE, compu {identical; unit Kph}, range phys 0..400, unit=Kph
  app type Boolean: category=VALUE
  application record data type tVehicleSpd: category=STRUCTURE
    application record element Filtered: category=VALUE, type=Kph_0_to_400
    application record element Moving: category=VALUE, type=Boolean
    application record element Qf: category=VALUE, type=tQualityFactor
  app type Kph: category=VALUE, compu {identical; unit Kph}, unit=Kph
  app type Degrees_n720_0_to_720_0: category=VALUE, compu {identical; unit deg}, range phys -720..720, unit=deg
  application record data type tEstimatedSteeringPosition: category=STRUCTURE
    application record element Value: category=VALUE, type=Degrees_n720_0_to_720_0
    application record element Qf: category=VALUE, type=tQualityFactor
    application record element Confidence: category=VALUE, type=Percent
  app type Degrees: category=VALUE, compu {identical; unit deg}, unit=deg
  app type DegreesPerSec: category=VALUE, compu {identical; unit deg/S}, unit=deg/S
  application record data type tYawRateData: category=STRUCTURE
    application record element Value: category=VALUE, type=DegreesPerSec
    application record element Qf: category=VALUE, type=tQualityFactor
  app type NmPerSec: category=VALUE, compu {identical; unit Nm/s}, range phys -2048..2048, unit=Nm/s  # Rate of change of torque
  application record data type tInputTorque: category=STRUCTURE
    application record element Value: category=VALUE, type=Nm
    application record element Derivative: category=VALUE, type=NmPerSec
    application record element Qf: category=VALUE, type=tQualityFactor
  application record data type tExtendedQf: category=STRUCTURE  # Extended quality information for a signal, used in conjunction with tQualityFactor. Legal combinations are: Qf = QF_UNINITIALISED, QF_UNINITIALIZED: eQf should be ignored. Qf = QF_UNAVAILABLE: eQf should be ignored. Qf = QF_DEGRADED: eQf - may have any combination of LossOfRedundancy, LossOfIntegrity, ResolutionDegraded or Defaulted set to True. Qf = QF_FULL: eQf may only have LossOfRedundancy set to True.
    4 x application record element, all with category=VALUE, type=Boolean:
      IntegrityDegraded
      ResolutionDegraded
      LossOfRedundancy
      Defaulted
  application record data type tColumnPosition: category=STRUCTURE  # Measument of the Column position in degrees with range -720 - +720.
    application record element Value: category=VALUE, type=Degrees_n720_0_to_720_0
    application record element Qf: category=VALUE, type=tQualityFactor
    application record element EQf: category=STRUCTURE, type=tExtendedQf
  app type RevsPerSec: category=VALUE, compu {identical; unit revs/S}, unit=revs/S
  application record data type tColumnVelocity: category=STRUCTURE
    application record element Filtered: category=VALUE, type=RevsPerSec
    application record element Unfiltered: category=VALUE, type=RevsPerSec
    application record element Qf: category=VALUE, type=tQualityFactor
  8 x app type, all with category=VALUE:
    mm: compu {identical; unit mm}, unit=mm
    kN: compu {identical; unit kN}, unit=kN
    mmPerSec: compu {identical; unit mm/s}, unit=mm/s
    tEnableState: base-type=sint32, compu {0=ES_DISABLE, 1=ES_NOT_READY, 2=ES_ENABLE, 3=ES_SHUTTING_DOWN}  # EPP Abstraction status
    tHealthStatus: base-type=sint32, compu {0=HEALTH_NOT_CONFIGURED, 1=HEALTHY, 2=HEALTH_FAILED}  # Indication of the health status of an element of the system.
    tMaxTimeCapability: base-type=sint32, compu {0=TIME_30HRS, 1=TIME_11MIN, 2=TIME_10SEC, 3=TIME_UNLIMITED}  # Indication of the time an element of the system can continue to function within its defined operating parameters. This definition is used to allow elements to report there remaining safe life-span in the event of a failure.
    tAssistMode: base-type=sint32, compu-method=tAssistMode_Compu  # State values reported by the Assist Mode Controller
    tLimitedAssistMode: base-type=sint32, compu {0=ASSIST_NOT_LIMITED, 1=ASSIST_LIMITED}  # Indication of whether the assist state is at full capability or being limited.
  application record data type tAssistStates: category=STRUCTURE
    application record element AssistMode: category=VALUE, type=tAssistMode
    application record element LimitedAssistMode: category=VALUE, type=tLimitedAssistMode
  10 x app type, all with category=VALUE:
    tSegMode: base-type=sint32, compu-method=tSegMode_Compu  # Indicates the mode of the SEG
    Kph_0_0_to_400_0: compu {identical; unit Kph}, range phys 0..400, unit=Kph
    RevsPerSec_0_0_to_0_5: compu {identical; unit revs/S}, range phys 0..0.5, unit=revs/S
    ms_0_to_2500: compu {identical; unit mS}, range phys 0..2500, unit=mS
    UInt32: compu {identical}
    Percent_0_0_to_1_0: compu {identical; unit %}, range phys 0..1, unit=%
    PercentPerSec_0_1_to_50_0: compu {identical; unit %/s}, range phys 0.1..50, unit=%/s  # Rate of change of a percentage of any value.
    Percent_0_to_1: compu {identical; unit %}, range phys 0..1, unit=%
    PercentPerSec_1_to_100: compu {identical; unit %/s}, range phys 1..100, unit=%/s  # Rate of change of a percentage of any value.
    ms_500_to_5000: compu {identical; unit mS}, range phys 500..5000, unit=mS
package /DataTypeMappingSets
  data type mapping set MappingSet
    data-type-maps:
      application-data-type=Float32, implementation-data-type=Float32
      application-data-type=Nm_n255_0_to_255_0, implementation-data-type=Nm
      application-data-type=tQualityFactor, implementation-data-type=tQualityFactor
      application-data-type=Nm, implementation-data-type=Nm
      application-data-type=tAssistTorque, implementation-data-type=tAssistTorque
      application-data-type=Percent, implementation-data-type=Percent
      application-data-type=tAssistCapability, implementation-data-type=tAssistCapability
      application-data-type=Kph_0_to_400, implementation-data-type=Kph
      application-data-type=Boolean, implementation-data-type=Boolean
      application-data-type=Kph, implementation-data-type=Kph
      application-data-type=tVehicleSpd, implementation-data-type=tVehicleSpd
      application-data-type=Degrees_n720_0_to_720_0, implementation-data-type=Degrees
      application-data-type=Degrees, implementation-data-type=Degrees
      application-data-type=tEstimatedSteeringPosition, implementation-data-type=tEstimatedSteeringPosition
      application-data-type=DegreesPerSec, implementation-data-type=DegreesPerSec
      application-data-type=tYawRateData, implementation-data-type=tYawRateData
      application-data-type=NmPerSec, implementation-data-type=NmPerSec
      application-data-type=tInputTorque, implementation-data-type=tInputTorque
      application-data-type=tExtendedQf, implementation-data-type=tExtendedQf
      application-data-type=tColumnPosition, implementation-data-type=tColumnPosition
      application-data-type=RevsPerSec, implementation-data-type=RevsPerSec
      application-data-type=tColumnVelocity, implementation-data-type=tColumnVelocity
      application-data-type=mm, implementation-data-type=mm
      application-data-type=kN, implementation-data-type=kN
      application-data-type=mmPerSec, implementation-data-type=mmPerSec
      application-data-type=tEnableState, implementation-data-type=tEnableState
      application-data-type=tHealthStatus, implementation-data-type=tHealthStatus
      application-data-type=tMaxTimeCapability, implementation-data-type=tMaxTimeCapability
      application-data-type=tAssistMode, implementation-data-type=tAssistMode
      application-data-type=tLimitedAssistMode, implementation-data-type=tLimitedAssistMode
      application-data-type=tAssistStates, implementation-data-type=tAssistStates
      application-data-type=tSegMode, implementation-data-type=tSegMode
      application-data-type=Kph_0_0_to_400_0, implementation-data-type=Kph
      application-data-type=RevsPerSec_0_0_to_0_5, implementation-data-type=RevsPerSec
      application-data-type=UInt32, implementation-data-type=UInt32
      application-data-type=ms_0_to_2500, implementation-data-type=ms
      application-data-type=Percent_0_0_to_1_0, implementation-data-type=Percent
      application-data-type=PercentPerSec_0_1_to_50_0, implementation-data-type=PercentPerSec
      application-data-type=Percent_0_to_1, implementation-data-type=Percent
      application-data-type=PercentPerSec_1_to_100, implementation-data-type=PercentPerSec
      application-data-type=ms_500_to_5000, implementation-data-type=ms
package /SwAddrMethods
  7 x sw addr method, all with memory-allocation-keyword-policy=ADDR-METHOD-SHORT-NAME, section-type=CALIBRATION-ONLINE:
    VehicleTune
    PlatformTune
    DevelopmentTune
    SteeringTune
    SensorTune
    EppTune
    GearTune
package /MICROSAR/Dem_swc/DataTypes
  18 x impl type:
    Dem_EventIdType: range raw 1..65535, implementation-data-type=uint16
    Dem_RatioIdType: range raw 1..65535, implementation-data-type=uint16
    Dem_DTCStatusMaskType: range raw 0..255, implementation-data-type=uint8
    Dem_OperationCycleIdType: range raw 0..255, implementation-data-type=uint8
    Dem_DTCGroupType: range raw 0..16777215, implementation-data-type=uint32
    Dem_MaxDataValueType: category=ARRAY, sw-calibration-access=READ-ONLY
      element Dem_MaxDataValueTypeElement: array-size=1, array-size-semantics=FIXED-SIZE, implementation-data-type=uint8
    Dem_EventStatusType: compu {0=DEM_EVENT_STATUS_PASSED, 1=DEM_EVENT_STATUS_FAILED, 2=DEM_EVENT_STATUS_PREPASSED, 3=DEM_EVENT_STATUS_PREFAILED}, implementation-data-type=uint8
    Dem_EventStatusExtendedType: compu {1=DEM_UDS_STATUS_TF, 2=DEM_UDS_STATUS_TFTOC, 4=DEM_UDS_STATUS_PDTC, 8=DEM_UDS_STATUS_CDTC, 16=DEM_UDS_STATUS_TNCSLC, 32=DEM_UDS_STATUS_TFSLC, 64=DEM_UDS_STATUS_TNCTOC, 128=DEM_UDS_STATUS_WIR}, implementation-data-type=uint8
    Dem_InitMonitorReasonType: compu {1=DEM_INIT_MONITOR_CLEAR, 2=DEM_INIT_MONITOR_RESTART, 3=DEM_INIT_MONITOR_REENABLED, 4=DEM_INIT_MONITOR_STORAGE_REENABLED}, implementation-data-type=uint8
    Dem_DTCOriginType: compu {1=DEM_DTC_ORIGIN_PRIMARY_MEMORY, 2=DEM_DTC_ORIGIN_MIRROR_MEMORY, 3=DEM_DTC_ORIGIN_PERMANENT_MEMORY, 4=DEM_DTC_ORIGIN_SECONDARY_MEMORY, 4=DEM_DTC_ORIGIN_USERDEFINED_MEMORY_10, 4=DEM_DTC_ORIGIN_USERDEFINED_MEMORY_11, 4=DEM_DTC_ORIGIN_USERDEFINED_MEMORY_12, 4=DEM_DTC_ORIGIN_USERDEFINED_MEMORY_13, 4=DEM_DTC_ORIGIN_USERDEFINED_MEMORY_14, 4=DEM_DTC_ORIGIN_USERDEFINED_MEMORY_15, 4=DEM_DTC_ORIGIN_USERDEFINED_MEMORY_16, 4=DEM_DTC_ORIGIN_USERDEFINED_MEMORY_17, 4=DEM_DTC_ORIGIN_USERDEFINED_MEMORY_18, 4=DEM_DTC_ORIGIN_USERDEFINED_MEMORY_19, 4=DEM_DTC_ORIGIN_USERDEFINED_MEMORY_1A, 4=DEM_DTC_ORIGIN_USERDEFINED_MEMORY_1B, 4=DEM_DTC_ORIGIN_USERDEFINED_MEMORY_1C, 4=DEM_DTC_ORIGIN_USERDEFINED_MEMORY_1D, 4=DEM_DTC_ORIGIN_USERDEFINED_MEMORY_1E, 4=DEM_DTC_ORIGIN_USERDEFINED_MEMORY_1F, 4=DEM_DTC_ORIGIN_USERDEFINED_MEMORY_20, 4=DEM_DTC_ORIGIN_USERDEFINED_MEMORY_21, 4=DEM_DTC_ORIGIN_USERDEFINED_MEMORY_22, 4=DEM_DTC_ORIGIN_USERDEFINED_MEMORY_23, 4=DEM_DTC_ORIGIN_USERDEFINED_MEMORY_24, 4=DEM_DTC_ORIGIN_USERDEFINED_MEMORY_25, 4=DEM_DTC_ORIGIN_USERDEFINED_MEMORY_26, 4=DEM_DTC_ORIGIN_USERDEFINED_MEMORY_27, 4=DEM_DTC_ORIGIN_USERDEFINED_MEMORY_28, 4=DEM_DTC_ORIGIN_USERDEFINED_MEMORY_29, 4=DEM_DTC_ORIGIN_USERDEFINED_MEMORY_2A, 4=DEM_DTC_ORIGIN_USERDEFINED_MEMORY_2B, 4=DEM_DTC_ORIGIN_USERDEFINED_MEMORY_2C, 4=DEM_DTC_ORIGIN_USERDEFINED_MEMORY_2D, 4=DEM_DTC_ORIGIN_USERDEFINED_MEMORY_2E, 4=DEM_DTC_ORIGIN_USERDEFINED_MEMORY_2F, 4=DEM_DTC_ORIGIN_USERDEFINED_MEMORY_30, 4=DEM_DTC_ORIGIN_USERDEFINED_MEMORY_31, 4=DEM_DTC_ORIGIN_USERDEFINED_MEMORY_32, 4=DEM_DTC_ORIGIN_USERDEFINED_MEMORY_33, 4=DEM_DTC_ORIGIN_USERDEFINED_MEMORY_34, 4=DEM_DTC_ORIGIN_USERDEFINED_MEMORY_35, 4=DEM_DTC_ORIGIN_USERDEFINED_MEMORY_36, 4=DEM_DTC_ORIGIN_USERDEFINED_MEMORY_37, 4=DEM_DTC_ORIGIN_USERDEFINED_MEMORY_38, 4=DEM_DTC_ORIGIN_USERDEFINED_MEMORY_39, 4=DEM_DTC_ORIGIN_USERDEFINED_MEMORY_3A, 4=DEM_DTC_ORIGIN_USERDEFINED_MEMORY_3B, 4=DEM_DTC_ORIGIN_USERDEFINED_MEMORY_3C, 4=DEM_DTC_ORIGIN_USERDEFINED_MEMORY_3D, 4=DEM_DTC_ORIGIN_USERDEFINED_MEMORY_3E, 4=DEM_DTC_ORIGIN_USERDEFINED_MEMORY_3F, 4=DEM_DTC_ORIGIN_USERDEFINED_MEMORY_40, 4=DEM_DTC_ORIGIN_USERDEFINED_MEMORY_41, 4=DEM_DTC_ORIGIN_USERDEFINED_MEMORY_42, 4=DEM_DTC_ORIGIN_USERDEFINED_MEMORY_43, 4=DEM_DTC_ORIGIN_USERDEFINED_MEMORY_44, 4=DEM_DTC_ORIGIN_USERDEFINED_MEMORY_45, 4=DEM_DTC_ORIGIN_USERDEFINED_MEMORY_46, 4=DEM_DTC_ORIGIN_USERDEFINED_MEMORY_47, 4=DEM_DTC_ORIGIN_USERDEFINED_MEMORY_48, 4=DEM_DTC_ORIGIN_USERDEFINED_MEMORY_49, 4=DEM_DTC_ORIGIN_USERDEFINED_MEMORY_4A, 4=DEM_DTC_ORIGIN_USERDEFINED_MEMORY_4B, 4=DEM_DTC_ORIGIN_USERDEFINED_MEMORY_4C, 4=DEM_DTC_ORIGIN_USERDEFINED_MEMORY_4D, 4=DEM_DTC_ORIGIN_USERDEFINED_MEMORY_4E, 4=DEM_DTC_ORIGIN_USERDEFINED_MEMORY_4F, 4=DEM_DTC_ORIGIN_USERDEFINED_MEMORY_50, 4=DEM_DTC_ORIGIN_USERDEFINED_MEMORY_51, 4=DEM_DTC_ORIGIN_USERDEFINED_MEMORY_52, 4=DEM_DTC_ORIGIN_USERDEFINED_MEMORY_53, 4=DEM_DTC_ORIGIN_USERDEFINED_MEMORY_54, 4=DEM_DTC_ORIGIN_USERDEFINED_MEMORY_55, 4=DEM_DTC_ORIGIN_USERDEFINED_MEMORY_56, 4=DEM_DTC_ORIGIN_USERDEFINED_MEMORY_57, 4=DEM_DTC_ORIGIN_USERDEFINED_MEMORY_58, 4=DEM_DTC_ORIGIN_USERDEFINED_MEMORY_59, 4=DEM_DTC_ORIGIN_USERDEFINED_MEMORY_5A, 4=DEM_DTC_ORIGIN_USERDEFINED_MEMORY_5B, 4=DEM_DTC_ORIGIN_USERDEFINED_MEMORY_5C, 4=DEM_DTC_ORIGIN_USERDEFINED_MEMORY_5D, 4=DEM_DTC_ORIGIN_USERDEFINED_MEMORY_5E, 4=DEM_DTC_ORIGIN_USERDEFINED_MEMORY_5F, 4=DEM_DTC_ORIGIN_USERDEFINED_MEMORY_60, 4=DEM_DTC_ORIGIN_USERDEFINED_MEMORY_61, 4=DEM_DTC_ORIGIN_USERDEFINED_MEMORY_62, 4=DEM_DTC_ORIGIN_USERDEFINED_MEMORY_63, 4=DEM_DTC_ORIGIN_USERDEFINED_MEMORY_64, 4=DEM_DTC_ORIGIN_USERDEFINED_MEMORY_65, 4=DEM_DTC_ORIGIN_USERDEFINED_MEMORY_66, 4=DEM_DTC_ORIGIN_USERDEFINED_MEMORY_67, 4=DEM_DTC_ORIGIN_USERDEFINED_MEMORY_68, 4=DEM_DTC_ORIGIN_USERDEFINED_MEMORY_69, 4=DEM_DTC_ORIGIN_USERDEFINED_MEMORY_6A, 4=DEM_DTC_ORIGIN_USERDEFINED_MEMORY_6B, 4=DEM_DTC_ORIGIN_USERDEFINED_MEMORY_6C, 4=DEM_DTC_ORIGIN_USERDEFINED_MEMORY_6D, 4=DEM_DTC_ORIGIN_USERDEFINED_MEMORY_6E, 4=DEM_DTC_ORIGIN_USERDEFINED_MEMORY_6F, 4=DEM_DTC_ORIGIN_USERDEFINED_MEMORY_70, 4=DEM_DTC_ORIGIN_USERDEFINED_MEMORY_71, 4=DEM_DTC_ORIGIN_USERDEFINED_MEMORY_72, 4=DEM_DTC_ORIGIN_USERDEFINED_MEMORY_73, 4=DEM_DTC_ORIGIN_USERDEFINED_MEMORY_74, 4=DEM_DTC_ORIGIN_USERDEFINED_MEMORY_75, 4=DEM_DTC_ORIGIN_USERDEFINED_MEMORY_76, 4=DEM_DTC_ORIGIN_USERDEFINED_MEMORY_77, 4=DEM_DTC_ORIGIN_USERDEFINED_MEMORY_78, 4=DEM_DTC_ORIGIN_USERDEFINED_MEMORY_79, 4=DEM_DTC_ORIGIN_USERDEFINED_MEMORY_7A, 4=DEM_DTC_ORIGIN_USERDEFINED_MEMORY_7B, 4=DEM_DTC_ORIGIN_USERDEFINED_MEMORY_7C, 4=DEM_DTC_ORIGIN_USERDEFINED_MEMORY_7D, 4=DEM_DTC_ORIGIN_USERDEFINED_MEMORY_7E, 4=DEM_DTC_ORIGIN_USERDEFINED_MEMORY_7F, 4=DEM_DTC_ORIGIN_USERDEFINED_MEMORY_80, 4=DEM_DTC_ORIGIN_USERDEFINED_MEMORY_81, 4=DEM_DTC_ORIGIN_USERDEFINED_MEMORY_82, 4=DEM_DTC_ORIGIN_USERDEFINED_MEMORY_83, 4=DEM_DTC_ORIGIN_USERDEFINED_MEMORY_84, 4=DEM_DTC_ORIGIN_USERDEFINED_MEMORY_85, 4=DEM_DTC_ORIGIN_USERDEFINED_MEMORY_86, 4=DEM_DTC_ORIGIN_USERDEFINED_MEMORY_87, 4=DEM_DTC_ORIGIN_USERDEFINED_MEMORY_88, 4=DEM_DTC_ORIGIN_USERDEFINED_MEMORY_89, 4=DEM_DTC_ORIGIN_USERDEFINED_MEMORY_8A, 4=DEM_DTC_ORIGIN_USERDEFINED_MEMORY_8B, 4=DEM_DTC_ORIGIN_USERDEFINED_MEMORY_8C, 4=DEM_DTC_ORIGIN_USERDEFINED_MEMORY_8D, 4=DEM_DTC_ORIGIN_USERDEFINED_MEMORY_8E, 4=DEM_DTC_ORIGIN_USERDEFINED_MEMORY_8F, 4=DEM_DTC_ORIGIN_USERDEFINED_MEMORY_90, 4=DEM_DTC_ORIGIN_USERDEFINED_MEMORY_91, 4=DEM_DTC_ORIGIN_USERDEFINED_MEMORY_92, 4=DEM_DTC_ORIGIN_USERDEFINED_MEMORY_93, 4=DEM_DTC_ORIGIN_USERDEFINED_MEMORY_94, 4=DEM_DTC_ORIGIN_USERDEFINED_MEMORY_95, 4=DEM_DTC_ORIGIN_USERDEFINED_MEMORY_96, 4=DEM_DTC_ORIGIN_USERDEFINED_MEMORY_97, 4=DEM_DTC_ORIGIN_USERDEFINED_MEMORY_98, 4=DEM_DTC_ORIGIN_USERDEFINED_MEMORY_99, 4=DEM_DTC_ORIGIN_USERDEFINED_MEMORY_9A, 4=DEM_DTC_ORIGIN_USERDEFINED_MEMORY_9B, 4=DEM_DTC_ORIGIN_USERDEFINED_MEMORY_9C, 4=DEM_DTC_ORIGIN_USERDEFINED_MEMORY_9D, 4=DEM_DTC_ORIGIN_USERDEFINED_MEMORY_9E, 4=DEM_DTC_ORIGIN_USERDEFINED_MEMORY_9F, 4=DEM_DTC_ORIGIN_USERDEFINED_MEMORY_A0, 4=DEM_DTC_ORIGIN_USERDEFINED_MEMORY_A1, 4=DEM_DTC_ORIGIN_USERDEFINED_MEMORY_A2, 4=DEM_DTC_ORIGIN_USERDEFINED_MEMORY_A3, 4=DEM_DTC_ORIGIN_USERDEFINED_MEMORY_A4, 4=DEM_DTC_ORIGIN_USERDEFINED_MEMORY_A5, 4=DEM_DTC_ORIGIN_USERDEFINED_MEMORY_A6, 4=DEM_DTC_ORIGIN_USERDEFINED_MEMORY_A7, 4=DEM_DTC_ORIGIN_USERDEFINED_MEMORY_A8, 4=DEM_DTC_ORIGIN_USERDEFINED_MEMORY_A9, 4=DEM_DTC_ORIGIN_USERDEFINED_MEMORY_AA, 4=DEM_DTC_ORIGIN_USERDEFINED_MEMORY_AB, 4=DEM_DTC_ORIGIN_USERDEFINED_MEMORY_AC, 4=DEM_DTC_ORIGIN_USERDEFINED_MEMORY_AD, 4=DEM_DTC_ORIGIN_USERDEFINED_MEMORY_AE, 4=DEM_DTC_ORIGIN_USERDEFINED_MEMORY_AF, 4=DEM_DTC_ORIGIN_USERDEFINED_MEMORY_B0, 4=DEM_DTC_ORIGIN_USERDEFINED_MEMORY_B1, 4=DEM_DTC_ORIGIN_USERDEFINED_MEMORY_B2, 4=DEM_DTC_ORIGIN_USERDEFINED_MEMORY_B3, 4=DEM_DTC_ORIGIN_USERDEFINED_MEMORY_B4, 4=DEM_DTC_ORIGIN_USERDEFINED_MEMORY_B5, 4=DEM_DTC_ORIGIN_USERDEFINED_MEMORY_B6, 4=DEM_DTC_ORIGIN_USERDEFINED_MEMORY_B7, 4=DEM_DTC_ORIGIN_USERDEFINED_MEMORY_B8, 4=DEM_DTC_ORIGIN_USERDEFINED_MEMORY_B9, 4=DEM_DTC_ORIGIN_USERDEFINED_MEMORY_BA, 4=DEM_DTC_ORIGIN_USERDEFINED_MEMORY_BB, 4=DEM_DTC_ORIGIN_USERDEFINED_MEMORY_BC, 4=DEM_DTC_ORIGIN_USERDEFINED_MEMORY_BD, 4=DEM_DTC_ORIGIN_USERDEFINED_MEMORY_BE, 4=DEM_DTC_ORIGIN_USERDEFINED_MEMORY_BF, 4=DEM_DTC_ORIGIN_USERDEFINED_MEMORY_C0, 4=DEM_DTC_ORIGIN_USERDEFINED_MEMORY_C1, 4=DEM_DTC_ORIGIN_USERDEFINED_MEMORY_C2, 4=DEM_DTC_ORIGIN_USERDEFINED_MEMORY_C3, 4=DEM_DTC_ORIGIN_USERDEFINED_MEMORY_C4, 4=DEM_DTC_ORIGIN_USERDEFINED_MEMORY_C5, 4=DEM_DTC_ORIGIN_USERDEFINED_MEMORY_C6, 4=DEM_DTC_ORIGIN_USERDEFINED_MEMORY_C7, 4=DEM_DTC_ORIGIN_USERDEFINED_MEMORY_C8, 4=DEM_DTC_ORIGIN_USERDEFINED_MEMORY_C9, 4=DEM_DTC_ORIGIN_USERDEFINED_MEMORY_CA, 4=DEM_DTC_ORIGIN_USERDEFINED_MEMORY_CB, 4=DEM_DTC_ORIGIN_USERDEFINED_MEMORY_CC, 4=DEM_DTC_ORIGIN_USERDEFINED_MEMORY_CD, 4=DEM_DTC_ORIGIN_USERDEFINED_MEMORY_CE, 4=DEM_DTC_ORIGIN_USERDEFINED_MEMORY_CF, 4=DEM_DTC_ORIGIN_USERDEFINED_MEMORY_D0, 4=DEM_DTC_ORIGIN_USERDEFINED_MEMORY_D1, 4=DEM_DTC_ORIGIN_USERDEFINED_MEMORY_D2, 4=DEM_DTC_ORIGIN_USERDEFINED_MEMORY_D3, 4=DEM_DTC_ORIGIN_USERDEFINED_MEMORY_D4, 4=DEM_DTC_ORIGIN_USERDEFINED_MEMORY_D5, 4=DEM_DTC_ORIGIN_USERDEFINED_MEMORY_D6, 4=DEM_DTC_ORIGIN_USERDEFINED_MEMORY_D7, 4=DEM_DTC_ORIGIN_USERDEFINED_MEMORY_D8, 4=DEM_DTC_ORIGIN_USERDEFINED_MEMORY_D9, 4=DEM_DTC_ORIGIN_USERDEFINED_MEMORY_DA, 4=DEM_DTC_ORIGIN_USERDEFINED_MEMORY_DB, 4=DEM_DTC_ORIGIN_USERDEFINED_MEMORY_DC, 4=DEM_DTC_ORIGIN_USERDEFINED_MEMORY_DD, 4=DEM_DTC_ORIGIN_USERDEFINED_MEMORY_DE, 4=DEM_DTC_ORIGIN_USERDEFINED_MEMORY_DF, 4=DEM_DTC_ORIGIN_USERDEFINED_MEMORY_E0, 4=DEM_DTC_ORIGIN_USERDEFINED_MEMORY_E1, 4=DEM_DTC_ORIGIN_USERDEFINED_MEMORY_E2, 4=DEM_DTC_ORIGIN_USERDEFINED_MEMORY_E3, 4=DEM_DTC_ORIGIN_USERDEFINED_MEMORY_E4, 4=DEM_DTC_ORIGIN_USERDEFINED_MEMORY_E5, 4=DEM_DTC_ORIGIN_USERDEFINED_MEMORY_E6, 4=DEM_DTC_ORIGIN_USERDEFINED_MEMORY_E7, 4=DEM_DTC_ORIGIN_USERDEFINED_MEMORY_E8, 4=DEM_DTC_ORIGIN_USERDEFINED_MEMORY_E9, 4=DEM_DTC_ORIGIN_USERDEFINED_MEMORY_EA, 4=DEM_DTC_ORIGIN_USERDEFINED_MEMORY_EB, 4=DEM_DTC_ORIGIN_USERDEFINED_MEMORY_EC, 4=DEM_DTC_ORIGIN_USERDEFINED_MEMORY_ED, 4=DEM_DTC_ORIGIN_USERDEFINED_MEMORY_EE, 4=DEM_DTC_ORIGIN_USERDEFINED_MEMORY_EF, 4=DEM_DTC_ORIGIN_USERDEFINED_MEMORY_F0, 4=DEM_DTC_ORIGIN_USERDEFINED_MEMORY_F1, 4=DEM_DTC_ORIGIN_USERDEFINED_MEMORY_F2, 4=DEM_DTC_ORIGIN_USERDEFINED_MEMORY_F3, 4=DEM_DTC_ORIGIN_USERDEFINED_MEMORY_F4, 4=DEM_DTC_ORIGIN_USERDEFINED_MEMORY_F5, 4=DEM_DTC_ORIGIN_USERDEFINED_MEMORY_F6, 4=DEM_DTC_ORIGIN_USERDEFINED_MEMORY_F7, 4=DEM_DTC_ORIGIN_USERDEFINED_MEMORY_F8, 4=DEM_DTC_ORIGIN_USERDEFINED_MEMORY_F9, 4=DEM_DTC_ORIGIN_USERDEFINED_MEMORY_FA, 4=DEM_DTC_ORIGIN_USERDEFINED_MEMORY_FB, 4=DEM_DTC_ORIGIN_USERDEFINED_MEMORY_FC, 4=DEM_DTC_ORIGIN_USERDEFINED_MEMORY_FD, 4=DEM_DTC_ORIGIN_USERDEFINED_MEMORY_FE, 4=DEM_DTC_ORIGIN_USERDEFINED_MEMORY_FF}, implementation-data-type=uint8
    Dem_DTCFormatType: compu {0=DEM_DTC_FORMAT_OBD, 1=DEM_DTC_FORMAT_UDS, 2=DEM_DTC_FORMAT_J1939}, implementation-data-type=uint8
    Dem_OperationCycleStateType: compu {0=DEM_CYCLE_STATE_START, 1=DEM_CYCLE_STATE_END}, implementation-data-type=uint8
    Dem_IndicatorStatusType: compu {0=DEM_INDICATOR_OFF, 1=DEM_INDICATOR_CONTINUOUS, 2=DEM_INDICATOR_BLINKING, 3=DEM_INDICATOR_BLINK_CONT, 4=DEM_INDICATOR_SLOW_FLASH, 5=DEM_INDICATOR_FAST_FLASH, 6=DEM_INDICATOR_ON_DEMAND, 7=DEM_INDICATOR_SHORT}, implementation-data-type=uint8
    Dem_DTCKindType: compu {1=DEM_DTC_KIND_ALL_DTCS, 2=DEM_DTC_KIND_EMISSION_REL_DTCS}, implementation-data-type=uint8
    Dem_IumprDenomCondIdType: compu {1=DEM_IUMPR_GENERAL_DENOMINATOR, 2=DEM_IUMPR_DEN_COND_COLDSTART, 3=DEM_IUMPR_DEN_COND_EVAP, 4=DEM_IUMPR_DEN_COND_500MI}, implementation-data-type=uint8
    Dem_IumprDenomCondStatusType: compu {0=DEM_IUMPR_DEN_STATUS_NOT_REACHED, 1=DEM_IUMPR_DEN_STATUS_REACHED, 2=DEM_IUMPR_DEN_STATUS_INHIBITED}, implementation-data-type=uint8
    Dem_DebounceResetStatusType: compu {0=DEM_DEBOUNCE_STATUS_FREEZE, 1=DEM_DEBOUNCE_STATUS_RESET}, implementation-data-type=uint8
    Dem_DebouncingStateType: compu {1=DEM_TEMPORARILY_DEFECTIVE, 2=DEM_FINALLY_DEFECTIVE, 4=DEM_TEMPORARILY_HEALED, 8=DEM_TEST_COMPLETE, 16=DEM_DTR_UPDATE}, implementation-data-type=uint8
package /MICROSAR/Dem_swc/Interfaces
  10 x client server interface, all with is-service=true, service-kind=DIAGNOSTIC-EVENT-MANAGER:
    CddIf
      operation ClearDTC: possible-error=[CddIf/DEM_CLEAR_WRONG_DTC, CddIf/DEM_CLEAR_WRONG_DTCORIGIN, CddIf/DEM_CLEAR_FAILED, CddIf/DEM_CLEAR_PENDING, CddIf/DEM_CLEAR_BUSY, CddIf/DEM_CLEAR_MEMORY_ERROR]
        arg DTC: type=uint32, direction=IN
        arg DTCFormat: type=Dem_DTCFormatType, direction=IN
        arg DTCOrigin: type=Dem_DTCOriginType, direction=IN
      6 x error:
        DEM_CLEAR_WRONG_DTC: error-code=1
        DEM_CLEAR_WRONG_DTCORIGIN: error-code=2
        DEM_CLEAR_FAILED: error-code=3
        DEM_CLEAR_PENDING: error-code=4
        DEM_CLEAR_BUSY: error-code=5
        DEM_CLEAR_MEMORY_ERROR: error-code=6
    DemServices
      operation GetPostRunRequested: possible-error=DemServices/E_NOT_OK
        arg IsRequested: type=boolean, direction=OUT
      operation GetDTCStatusAvailabilityMask: possible-error=DemServices/E_NOT_OK
        arg DTCStatusMask: type=uint8, direction=OUT
      error E_NOT_OK: error-code=1
    GeneralDiagnosticInfo
      9 x operation:
        GetEventStatus: possible-error=GeneralDiagnosticInfo/E_NOT_OK
          arg EventId: type=Dem_EventIdType, direction=IN
          arg EventStatusExtended: type=Dem_EventStatusExtendedType, direction=OUT
        GetEventFailed: possible-error=GeneralDiagnosticInfo/E_NOT_OK
          arg EventId: type=Dem_EventIdType, direction=IN
          arg EventFailed: type=boolean, direction=OUT
        GetEventTested: possible-error=GeneralDiagnosticInfo/E_NOT_OK
          arg EventId: type=Dem_EventIdType, direction=IN
          arg EventTested: type=boolean, direction=OUT
        GetDTCOfEvent: possible-error=[GeneralDiagnosticInfo/E_NOT_OK, GeneralDiagnosticInfo/DEM_E_NO_DTC_AVAILABLE]
          arg EventId: type=Dem_EventIdType, direction=IN
          arg DTCFormat: type=Dem_DTCFormatType, direction=IN
          arg DTCOfEvent: type=uint32, direction=OUT
        GetFaultDetectionCounter: possible-error=[GeneralDiagnosticInfo/E_NOT_OK, GeneralDiagnosticInfo/DEM_E_NO_FDC_AVAILABLE]
          arg EventId: type=Dem_EventIdType, direction=IN
          arg FaultDetectionCounter: type=sint8, direction=OUT
        GetEventFreezeFrameData: possible-error=[GeneralDiagnosticInfo/E_NOT_OK, GeneralDiagnosticInfo/DEM_E_NODATAAVAILABLE, GeneralDiagnosticInfo/DEM_E_WRONG_RECORDNUMBER, GeneralDiagnosticInfo/DEM_E_WRONG_DIDNUMBER]
          5 x arg:
            EventId: type=Dem_EventIdType, direction=IN
            RecordNumber: type=uint8, direction=IN
            ReportTotalRecord: type=boolean, direction=IN
            DataId: type=uint16, direction=IN
            DestBuffer: type=Dem_MaxDataValueType, direction=OUT
        GetEventExtendedDataRecord: possible-error=[GeneralDiagnosticInfo/E_NOT_OK, GeneralDiagnosticInfo/DEM_E_NODATAAVAILABLE, GeneralDiagnosticInfo/DEM_E_WRONG_RECORDNUMBER]
          arg EventId: type=Dem_EventIdType, direction=IN
          arg RecordNumber: type=uint8, direction=IN
          arg DestBuffer: type=Dem_MaxDataValueType, direction=OUT
        GetEventEnableCondition: possible-error=GeneralDiagnosticInfo/E_NOT_OK
          arg EventId: type=Dem_EventIdType, direction=IN
          arg ConditionFullfilled: type=boolean, direction=OUT
        GetDebouncingOfEvent: possible-error=GeneralDiagnosticInfo/E_NOT_OK
          arg EventId: type=Dem_EventIdType, direction=IN
          arg DebouncingState: type=Dem_DebouncingStateType, direction=OUT
      6 x error:
        E_NOT_OK: error-code=1
        DEM_E_NO_DTC_AVAILABLE: error-code=2
        DEM_E_NO_FDC_AVAILABLE: error-code=3
        DEM_E_NODATAAVAILABLE: error-code=48
        DEM_E_WRONG_RECORDNUMBER: error-code=49
        DEM_E_WRONG_DIDNUMBER: error-code=50
    DiagnosticInfo
      9 x operation:
        GetEventStatus: possible-error=DiagnosticInfo/E_NOT_OK
          arg EventStatusExtended: type=Dem_EventStatusExtendedType, direction=OUT
        GetEventFailed: possible-error=DiagnosticInfo/E_NOT_OK
          arg EventFailed: type=boolean, direction=OUT
        GetEventTested: possible-error=DiagnosticInfo/E_NOT_OK
          arg EventTested: type=boolean, direction=OUT
        GetDTCOfEvent: possible-error=[DiagnosticInfo/E_NOT_OK, DiagnosticInfo/DEM_E_NO_DTC_AVAILABLE]
          arg DTCFormat: type=Dem_DTCFormatType, direction=IN
          arg DTCOfEvent: type=uint32, direction=OUT
        GetFaultDetectionCounter: possible-error=[DiagnosticInfo/E_NOT_OK, DiagnosticInfo/DEM_E_NO_FDC_AVAILABLE]
          arg FaultDetectionCounter: type=sint8, direction=OUT
        GetEventFreezeFrameData: possible-error=[DiagnosticInfo/E_NOT_OK, DiagnosticInfo/DEM_E_NODATAAVAILABLE, DiagnosticInfo/DEM_E_WRONG_RECORDNUMBER, DiagnosticInfo/DEM_E_WRONG_DIDNUMBER]
          4 x arg:
            RecordNumber: type=uint8, direction=IN
            ReportTotalRecord: type=boolean, direction=IN
            DataId: type=uint16, direction=IN
            DestBuffer: type=Dem_MaxDataValueType, direction=OUT
        GetEventExtendedDataRecord: possible-error=[DiagnosticInfo/E_NOT_OK, DiagnosticInfo/DEM_E_NODATAAVAILABLE, DiagnosticInfo/DEM_E_WRONG_RECORDNUMBER]
          arg RecordNumber: type=uint8, direction=IN
          arg DestBuffer: type=Dem_MaxDataValueType, direction=OUT
        GetEventEnableCondition: possible-error=DiagnosticInfo/E_NOT_OK
          arg ConditionFullfilled: type=boolean, direction=OUT
        GetDebouncingOfEvent: possible-error=DiagnosticInfo/E_NOT_OK
          arg DebouncingState: type=Dem_DebouncingStateType, direction=OUT
      6 x error:
        E_NOT_OK: error-code=1
        DEM_E_NO_DTC_AVAILABLE: error-code=2
        DEM_E_NO_FDC_AVAILABLE: error-code=3
        DEM_E_NODATAAVAILABLE: error-code=48
        DEM_E_WRONG_RECORDNUMBER: error-code=49
        DEM_E_WRONG_DIDNUMBER: error-code=50
    DiagnosticMonitor
      10 x operation:
        SetEventStatus: possible-error=DiagnosticMonitor/E_NOT_OK
          arg EventStatus: type=Dem_EventStatusType, direction=IN
        ResetEventStatus: possible-error=DiagnosticMonitor/E_NOT_OK
        ResetEventDebounceStatus: possible-error=DiagnosticMonitor/E_NOT_OK
          arg DebounceResetStatus: type=Dem_DebounceResetStatusType, direction=IN
        GetEventStatus: possible-error=DiagnosticMonitor/E_NOT_OK
          arg EventStatusExtended: type=Dem_EventStatusExtendedType, direction=OUT
        GetEventFailed: possible-error=DiagnosticMonitor/E_NOT_OK
          arg EventFailed: type=boolean, direction=OUT
        GetEventTested: possible-error=DiagnosticMonitor/E_NOT_OK
          arg EventTested: type=boolean, direction=OUT
        GetDTCOfEvent: possible-error=[DiagnosticMonitor/E_NOT_OK, DiagnosticMonitor/DEM_E_NO_DTC_AVAILABLE]
          arg DTCFormat: type=Dem_DTCFormatType, direction=IN
          arg DTCOfEvent: type=uint32, direction=OUT
        GetFaultDetectionCounter: possible-error=[DiagnosticMonitor/E_NOT_OK, DiagnosticMonitor/DEM_E_NO_FDC_AVAILABLE]
          arg FaultDetectionCounter: type=sint8, direction=OUT
        GetEventFreezeFrameData: possible-error=[DiagnosticMonitor/E_NOT_OK, DiagnosticMonitor/DEM_E_NODATAAVAILABLE, DiagnosticMonitor/DEM_E_WRONG_RECORDNUMBER, DiagnosticMonitor/DEM_E_WRONG_DIDNUMBER]
          4 x arg:
            RecordNumber: type=uint8, direction=IN
            ReportTotalRecord: type=boolean, direction=IN
            DataId: type=uint16, direction=IN
            DestBuffer: type=Dem_MaxDataValueType, direction=OUT
        GetEventExtendedDataRecord: possible-error=[DiagnosticMonitor/E_NOT_OK, DiagnosticMonitor/DEM_E_NODATAAVAILABLE, DiagnosticMonitor/DEM_E_WRONG_RECORDNUMBER]
          arg RecordNumber: type=uint8, direction=IN
          arg DestBuffer: type=Dem_MaxDataValueType, direction=OUT
      6 x error:
        E_NOT_OK: error-code=1
        DEM_E_NO_DTC_AVAILABLE: error-code=2
        DEM_E_NO_FDC_AVAILABLE: error-code=3
        DEM_E_NODATAAVAILABLE: error-code=48
        DEM_E_WRONG_RECORDNUMBER: error-code=49
        DEM_E_WRONG_DIDNUMBER: error-code=50
    DcmIf
      5 x operation:
        DcmClearDTC: possible-error=[DcmIf/DEM_CLEAR_WRONG_DTC, DcmIf/DEM_CLEAR_WRONG_DTCORIGIN, DcmIf/DEM_CLEAR_FAILED, DcmIf/DEM_CLEAR_PENDING, DcmIf/DEM_CLEAR_BUSY, DcmIf/DEM_CLEAR_MEMORY_ERROR]
          arg DTC: type=uint32, direction=IN
          arg DTCFormat: type=Dem_DTCFormatType, direction=IN
          arg DTCOrigin: type=Dem_DTCOriginType, direction=IN
        DcmGetNextFilteredDTCAndFDC: possible-error=DEM_FILTERED_NO_MATCHING_DTC
          arg DTC: type=uint32, direction=OUT
          arg DTCFaultDetectionCounter: type=sint8, direction=OUT
        DcmEnableDTCSetting: possible-error=[DEM_CONTROL_DTC_SETTING_N_OK, DEM_CONTROL_DTC_WRONG_DTCGROUP]
          arg DTCGroup: type=Dem_DTCGroupType, direction=IN
          arg DTCKind: type=Dem_DTCKindType, direction=IN
        DcmGetFreezeFrameDataByDTC: possible-error=[DEM_GET_FFDATABYDTC_WRONG_DTC, DEM_GET_FFDATABYDTC_WRONG_DTCORIGIN, DEM_GET_FFDATABYDTC_WRONG_RECORDNUMBER, DEM_GET_FFDATABYDTC_WRONG_BUFFERSIZE, DEM_GET_FFDATABYDTC_PENDING]
          5 x arg:
            DTC: type=uint32, direction=IN
            DTCOrigin: type=Dem_DTCOriginType, direction=IN
            RecordNumber: type=uint8, direction=IN
            DestBuffer: type=uint8, direction=OUT
            BufSize: type=uint16, direction=INOUT
        DcmGetExtendedDataRecordByDTC: possible-error=[DEM_RECORD_WRONG_DTC, DEM_RECORD_WRONG_DTCORIGIN, DEM_RECORD_WRONG_NUMBER, DEM_RECORD_WRONG_BUFFERSIZE, DEM_RECORD_PENDING]
          5 x arg:
            DTC: type=uint32, direction=IN
            DTCOrigin: type=Dem_DTCOriginType, direction=IN
            ExtendedDataNumber: type=uint8, direction=IN
            DestBuffer: type=uint8, direction=OUT
            BufSize: type=uint16, direction=INOUT
      19 x error:
        DEM_CLEAR_WRONG_DTC: error-code=1
        DEM_CONTROL_DTC_SETTING_N_OK: error-code=1
        DEM_FILTERED_NO_MATCHING_DTC: error-code=1
        DEM_GET_FFDATABYDTC_WRONG_DTC: error-code=1
        DEM_RECORD_WRONG_DTC: error-code=1
        DEM_CLEAR_WRONG_DTCORIGIN: error-code=2
        DEM_CONTROL_DTC_WRONG_DTCGROUP: error-code=2
        DEM_GET_FFDATABYDTC_WRONG_DTCORIGIN: error-code=2
        DEM_RECORD_WRONG_DTCORIGIN: error-code=2
        DEM_CLEAR_FAILED: error-code=3
        DEM_GET_FFDATABYDTC_WRONG_RECORDNUMBER: error-code=3
        DEM_RECORD_WRONG_NUMBER: error-code=3
        DEM_CLEAR_PENDING: error-code=4
        DEM_GET_FFDATABYDTC_WRONG_BUFFERSIZE: error-code=4
        DEM_RECORD_WRONG_BUFFERSIZE: error-code=4
        DEM_CLEAR_BUSY: error-code=5
        DEM_GET_FFDATABYDTC_PENDING: error-code=5
        DEM_RECORD_PENDING: error-code=5
        DEM_CLEAR_MEMORY_ERROR: error-code=6
    OperationCycle
      operation SetOperationCycleState: possible-error=OperationCycle/E_NOT_OK
        arg CycleState: type=Dem_OperationCycleStateType, direction=IN
      error E_NOT_OK: error-code=1
    GeneralCallbackEventStatusChange
      operation EventStatusChanged
        arg EventId: type=Dem_EventIdType, direction=IN
        arg EventStatusOld: type=Dem_EventStatusExtendedType, direction=IN
        arg EventStatusNew: type=Dem_EventStatusExtendedType, direction=IN
    EvMemOverflowIndication
      operation GetEventMemoryOverflow: possible-error=EvMemOverflowIndication/E_NOT_OK
        arg OverflowIndication: type=boolean, direction=OUT
      operation GetNumberOfEventMemoryEntries: possible-error=EvMemOverflowIndication/E_NOT_OK
        arg NumberOfEventMemoryEntries: type=uint8, direction=OUT
      error E_NOT_OK: error-code=1
    EnableCondition
      operation SetEnableCondition: possible-error=EnableCondition/E_NOT_OK
        arg ConditionFulfilled: type=boolean, direction=IN
      error E_NOT_OK: error-code=1
